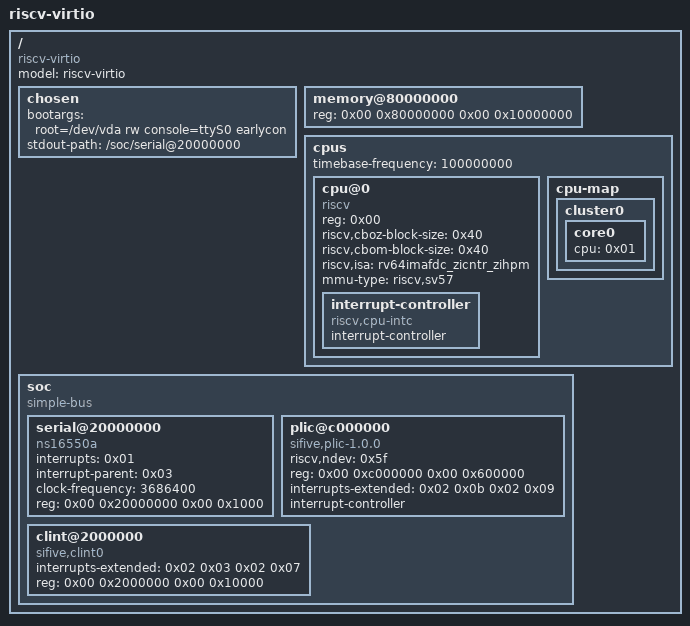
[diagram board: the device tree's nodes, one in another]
/dts-v1/;

/ {
	#address-cells = <0x02>;
	#size-cells = <0x02>;
	compatible = "riscv-virtio";
	model = "riscv-virtio";

	chosen {
		bootargs = "root=/dev/vda rw console=ttyS0 earlycon";
		//rng-seed = <0x25d69b2 0xff555073 0xd23238ea 0x57aa5455 0x792478ed 0xa744f28e 0x6ba4fc54 0xa2bf20fc>;
		stdout-path = "/soc/serial@20000000";
	};

	memory@80000000 {
		device_type = "memory";
//		reg = <0x00 0x80000000 0x01 0x00>;
// 		reg = <0x00 0x80000000 0x00 0x80000000>;
 		reg = <0x00 0x80000000 0x00 0x10000000>;
	};

	cpus {
		#address-cells = <0x01>;
		#size-cells = <0x00>;
		// timebase-frequency = <0x989680>;
		//timebase-frequency = <0x5f5e100>;
		timebase-frequency = <100000000>;

		cpu@0 {
			phandle = <0x01>;
			device_type = "cpu";
			reg = <0x00>;
			status = "okay";
			compatible = "riscv";
			riscv,cboz-block-size = <0x40>;
			riscv,cbom-block-size = <0x40>;
			//riscv,isa = "rv64imafdch_zicbom_zicboz_zicsr_zifencei_zihintpause_zawrs_zfa_zca_zcd_zba_zbb_zbc_zbs_sstc_svadu";
			riscv,isa = "rv64imafdc_zicntr_zihpm";
			mmu-type = "riscv,sv57";

			interrupt-controller {
				#interrupt-cells = <0x01>;
				interrupt-controller;
				compatible = "riscv,cpu-intc";
				phandle = <0x02>;
			};
		};

		cpu-map {

			cluster0 {

				core0 {
					cpu = <0x01>;
				};
			};
		};
	};

	soc {
		#address-cells = <0x02>;
		#size-cells = <0x02>;
		compatible = "simple-bus";
		ranges;

		serial@20000000 {
			interrupts = <0x01>;
			interrupt-parent = <0x03>;
			//clock-frequency = "\08@";
			clock-frequency = "3686400";
			reg = <0x00 0x20000000 0x00 0x1000>;
			compatible = "ns16550a";
		};

		plic@c000000 {
			phandle = <0x03>;
			riscv,ndev = <0x5f>;
			reg = <0x00 0xc000000 0x00 0x600000>;
			interrupts-extended = <0x02 0x0b 0x02 0x09>;
			interrupt-controller;
			compatible = "sifive,plic-1.0.0\0riscv,plic0";
			#address-cells = <0x00>;
			#interrupt-cells = <0x01>;
		};

		clint@2000000 {
			interrupts-extended = <0x02 0x03 0x02 0x07>;
			reg = <0x00 0x2000000 0x00 0x10000>;
			compatible = "sifive,clint0\0riscv,clint0";
		};
	};
};
